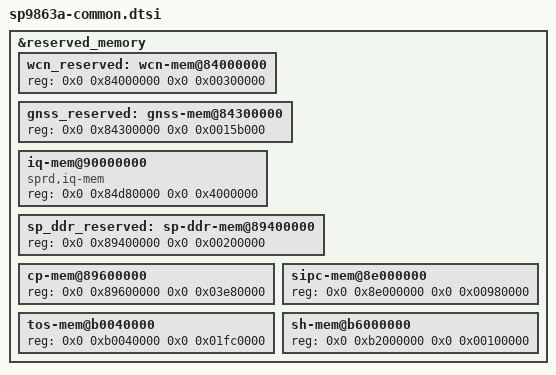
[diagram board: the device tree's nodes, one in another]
// SPDX-License-Identifier: (GPL-2.0+ OR MIT)

#include "modem-4g-common.dtsi"

&reserved_memory {
	wcn_reserved: wcn-mem@84000000 {
		reg = <0x0 0x84000000 0x0 0x00300000>;
	};

	gnss_reserved: gnss-mem@84300000 {
		reg = <0x0 0x84300000 0x0 0x0015b000>;
	};

/* Only used for iq, will be removed in normal mode by uboot */
	iq-mem@90000000 {
		compatible = "sprd,iq-mem";
		reg = <0x0 0x84d80000 0x0 0x4000000>;
	};

	sp_ddr_reserved: sp-ddr-mem@89400000 {
		reg = <0x0 0x89400000 0x0 0x00200000>;
	};

	cp-mem@89600000 {
		reg = <0x0 0x89600000 0x0 0x03e80000>;
	};

	sipc-mem@8e000000 {
		reg = <0x0 0x8e000000 0x0 0x00980000>;
	};

	tos-mem@b0040000 {
		reg = <0x0 0xb0040000 0x0 0x01fc0000>;
	};

	sh-mem@b6000000 {
		reg = <0x0 0xb2000000 0x0 0x00100000>;
	};
};
